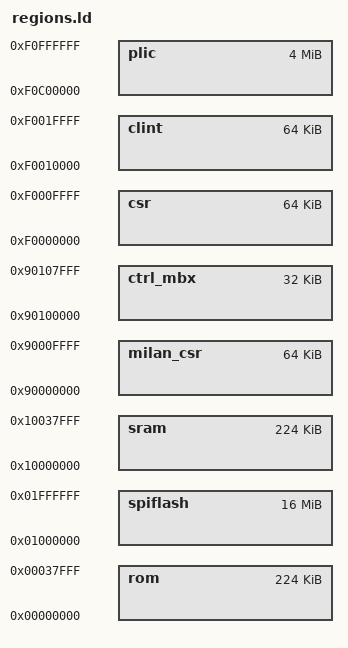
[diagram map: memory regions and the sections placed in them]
MEMORY {
	plic : ORIGIN = 0xf0c00000, LENGTH = 0x00400000
	clint : ORIGIN = 0xf0010000, LENGTH = 0x00010000
	rom : ORIGIN = 0x00000000, LENGTH = 0x00038000
	sram : ORIGIN = 0x10000000, LENGTH = 0x00038000
	spiflash : ORIGIN = 0x01000000, LENGTH = 0x01000000
	milan_csr : ORIGIN = 0x90000000, LENGTH = 0x00010000
	ctrl_mbx : ORIGIN = 0x90100000, LENGTH = 0x00008000
	csr : ORIGIN = 0xf0000000, LENGTH = 0x00010000
}
